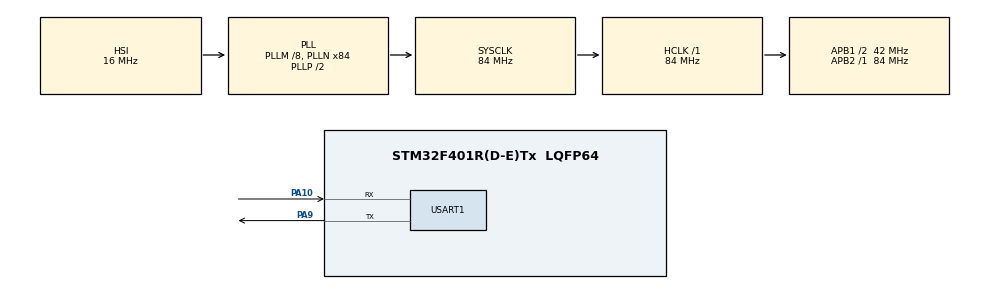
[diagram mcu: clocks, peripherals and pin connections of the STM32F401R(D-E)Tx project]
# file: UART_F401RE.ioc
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Mcu.Family=STM32F4
Mcu.Name=STM32F401R(D-E)Tx
Mcu.Package=LQFP64
NVIC.PriorityGroup=NVIC_PRIORITYGROUP_4
NVIC.USART1_IRQn=true\:0\:0\:false\:false\:true\:true\:true\:true
PA10.Mode=Asynchronous
PA10.Signal=USART1_RX
PA9.Mode=Asynchronous
PA9.Signal=USART1_TX
PH0\ -\ OSC_IN.Mode=HSE-External-Oscillator
PH0\ -\ OSC_IN.Signal=RCC_OSC_IN
PH1\ -\ OSC_OUT.Mode=HSE-External-Oscillator
PH1\ -\ OSC_OUT.Signal=RCC_OSC_OUT
ProjectManager.HeapSize=0x200
ProjectManager.StackSize=0x400
ProjectManager.TargetToolchain=STM32CubeIDE
RCC.48MHZClocksFreq_Value=42000000
RCC.AHBFreq_Value=84000000
RCC.APB1CLKDivider=RCC_HCLK_DIV2
RCC.APB1Freq_Value=42000000
RCC.APB1TimFreq_Value=84000000
RCC.APB2Freq_Value=84000000
RCC.APB2TimFreq_Value=84000000
RCC.CortexFreq_Value=84000000
RCC.HCLKFreq_Value=84000000
RCC.HSE_VALUE=8000000
RCC.HSI_VALUE=16000000
RCC.LSE_VALUE=32768
RCC.PLLM=8
RCC.PLLN=84
RCC.SYSCLKFreq_VALUE=84000000
RCC.SYSCLKSource=RCC_SYSCLKSOURCE_PLLCLK
RCC.VCOOutputFreq_Value=168000000
USART1.VirtualMode=VM_ASYNC
board=custom

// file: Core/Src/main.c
/* USER CODE BEGIN Header */
/**
  ******************************************************************************
  * @file           : main.c
  * @brief          : Main program body
  ******************************************************************************
  * @attention
  *
  * Copyright (c) 2025 STMicroelectronics.
  * All rights reserved.
  *
  * This software is licensed under terms that can be found in the LICENSE file
  * in the root directory of this software component.
  * If no LICENSE file comes with this software, it is provided AS-IS.
  *
  ******************************************************************************
  */
/* USER CODE END Header */
#include "main.h"

/* USER CODE BEGIN PM */
#define RX_BUFFER 30
/* USER CODE END PM */

UART_HandleTypeDef huart1;

/* USER CODE BEGIN PV */
//uint8_t rx_byte;
//char rx_buffer[RX_BUFFER];
//uint8_t rx_index = 0;
//char msg[] = "Hello\r\n";
uint8_t tx_data[]= "HELLO";
uint8_t Rx_buffer[RX_BUFFER];
/* USER CODE END PV */

void SystemClock_Config(void);
static void MX_GPIO_Init(void);
static void MX_USART1_UART_Init(void);

int main(void)
{

  /* MCU Configuration--------------------------------------------------------*/

  /* Reset of all peripherals, Initializes the Flash interface and the Systick. */
  HAL_Init();

  /* Configure the system clock */
  SystemClock_Config();

  /* Initialize all configured peripherals */
  MX_GPIO_Init();
  MX_USART1_UART_Init();
  /* USER CODE BEGIN 2 */
  HAL_UART_Receive_IT(&huart1, Rx_buffer, sizeof(Rx_buffer));

  /* USER CODE END 2 */

  /* Infinite loop */
  while (1)
  {

    /* USER CODE BEGIN 3 */
	  HAL_UART_Transmit_IT(&huart1, (uint8_t *)tx_data, sizeof(tx_data));
	  HAL_Delay(1000);
	  //HAL_UART_Transmit_IT(&huart1, (uint8_t *)msg, sizeof(msg));

  }
  /* USER CODE END 3 */
}

void SystemClock_Config(void)
{
  RCC_OscInitTypeDef RCC_OscInitStruct = {0};
  RCC_ClkInitTypeDef RCC_ClkInitStruct = {0};

  /** Configure the main internal regulator output voltage
  */
  __HAL_RCC_PWR_CLK_ENABLE();
  __HAL_PWR_VOLTAGESCALING_CONFIG(PWR_REGULATOR_VOLTAGE_SCALE2);

  /** Initializes the RCC Oscillators according to the specified parameters
  * in the RCC_OscInitTypeDef structure.
  */
  RCC_OscInitStruct.OscillatorType = RCC_OSCILLATORTYPE_HSI;
  RCC_OscInitStruct.HSIState = RCC_HSI_ON;
  RCC_OscInitStruct.HSICalibrationValue = RCC_HSICALIBRATION_DEFAULT;
  RCC_OscInitStruct.PLL.PLLState = RCC_PLL_ON;
  RCC_OscInitStruct.PLL.PLLSource = RCC_PLLSOURCE_HSI;
  RCC_OscInitStruct.PLL.PLLM = 8;
  RCC_OscInitStruct.PLL.PLLN = 84;
  RCC_OscInitStruct.PLL.PLLP = RCC_PLLP_DIV2;
  RCC_OscInitStruct.PLL.PLLQ = 4;
  if (HAL_RCC_OscConfig(&RCC_OscInitStruct) != HAL_OK)
  {
    Error_Handler();
  }

  /** Initializes the CPU, AHB and APB buses clocks
  */
  RCC_ClkInitStruct.ClockType = RCC_CLOCKTYPE_HCLK|RCC_CLOCKTYPE_SYSCLK
                              |RCC_CLOCKTYPE_PCLK1|RCC_CLOCKTYPE_PCLK2;
  RCC_ClkInitStruct.SYSCLKSource = RCC_SYSCLKSOURCE_PLLCLK;
  RCC_ClkInitStruct.AHBCLKDivider = RCC_SYSCLK_DIV1;
  RCC_ClkInitStruct.APB1CLKDivider = RCC_HCLK_DIV2;
  RCC_ClkInitStruct.APB2CLKDivider = RCC_HCLK_DIV1;

  if (HAL_RCC_ClockConfig(&RCC_ClkInitStruct, FLASH_LATENCY_2) != HAL_OK)
  {
    Error_Handler();
  }
}

static void MX_USART1_UART_Init(void)
{

  huart1.Instance = USART1;
  huart1.Init.BaudRate = 115200;
  huart1.Init.WordLength = UART_WORDLENGTH_8B;
  huart1.Init.StopBits = UART_STOPBITS_1;
  huart1.Init.Parity = UART_PARITY_NONE;
  huart1.Init.Mode = UART_MODE_TX_RX;
  huart1.Init.HwFlowCtl = UART_HWCONTROL_NONE;
  huart1.Init.OverSampling = UART_OVERSAMPLING_16;
  if (HAL_UART_Init(&huart1) != HAL_OK)
  {
    Error_Handler();
  }

}

static void MX_GPIO_Init(void)
{

  /* GPIO Ports Clock Enable */
  __HAL_RCC_GPIOH_CLK_ENABLE();
  __HAL_RCC_GPIOA_CLK_ENABLE();

}

/* USER CODE BEGIN 4 */
void HAL_UART_RxCpltCallback(UART_HandleTypeDef *huart)
{
    if (huart->Instance == USART1)
    {
//        // Store received byte into buffer
//        rx_buffer[rx_index++] = rx_byte;
//
//        // Check for end of message (newline)
//        if (rx_byte == '\n')
//        {
//            // Send back full buffer
//   //         HAL_UART_Transmit(&huart1, (uint8_t*)rx_buffer, rx_index, HAL_MAX_DELAY);
//            rx_index = 0; // reset buffer
//        }
//
//        // Restart reception for next byte

    	  HAL_UART_Receive_IT(&huart1, Rx_buffer, sizeof(Rx_buffer));
    }
}
/* USER CODE END 4 */

void Error_Handler(void)
{
  __disable_irq();
  while (1)
  {
  }
}
